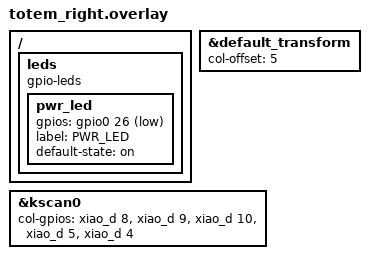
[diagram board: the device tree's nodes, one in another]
/*
 * Copyright (c) 2023 The ZMK Contributors
 *
 * SPDX-License-Identifier: MIT
 */

#include "totem.dtsi"

&default_transform {
    col-offset = <5>;
};

&kscan0 {
    col-gpios
        = <&xiao_d 8 GPIO_ACTIVE_HIGH>
        , <&xiao_d 9 GPIO_ACTIVE_HIGH>
        , <&xiao_d 10 GPIO_ACTIVE_HIGH>
        , <&xiao_d 5 GPIO_ACTIVE_HIGH>
        , <&xiao_d 4 GPIO_ACTIVE_HIGH>
        ;
};

/ {
    leds {
        compatible = "gpio-leds";

        pwr_led: pwr_led {
            gpios = <&gpio0 26 GPIO_ACTIVE_LOW>;
            label = "PWR_LED";
            default-state = "on";
        };
    };
};
